AUTOSAR XML (schema 4-2-2)
package /STELLANTIS/EPT/ASWCs
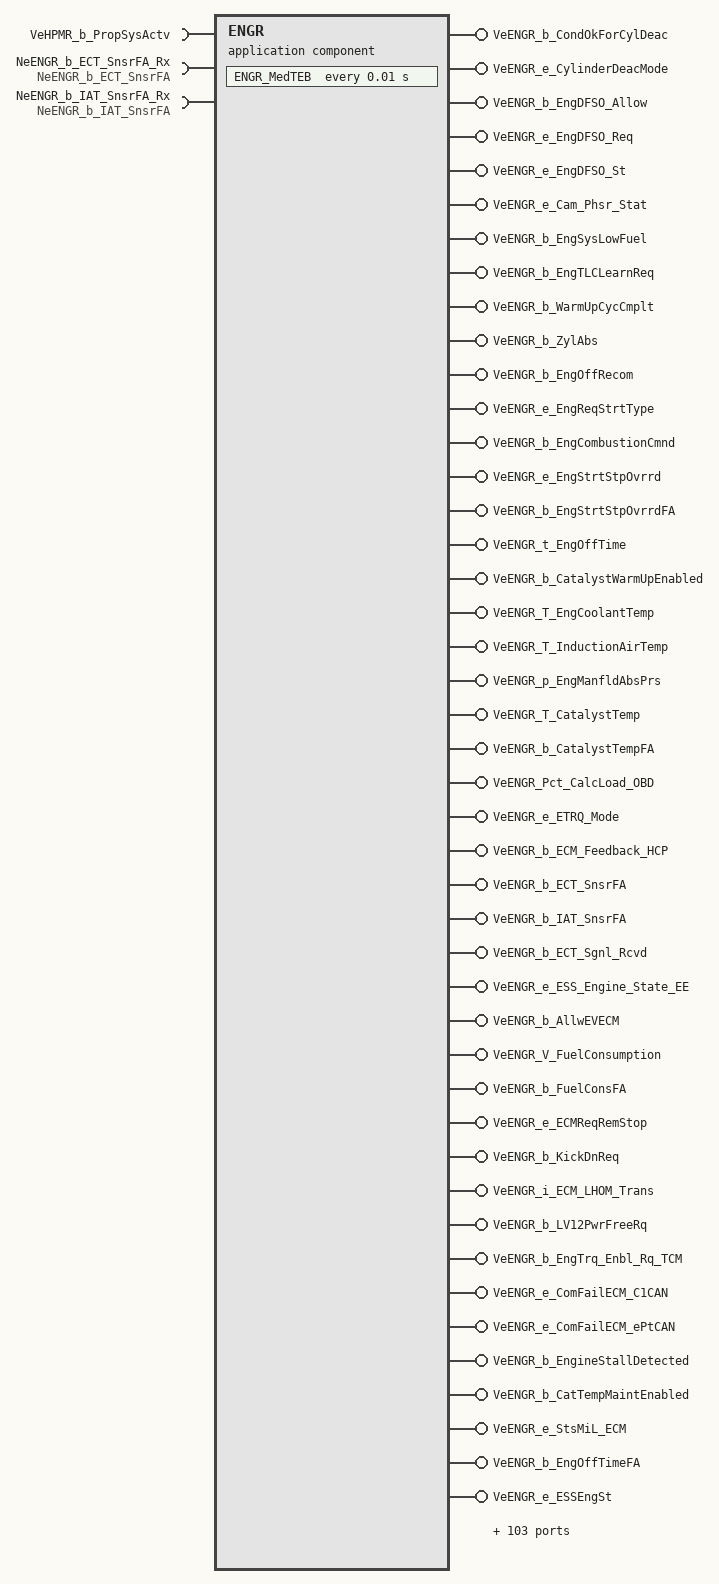
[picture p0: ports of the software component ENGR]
  application sw component type ENGR
    require port VeHPMR_b_PropSysActv: variation-point={short-label=vpVeHPMR_b_PropSysActv, sw-syscond=1}, nonqueued-receiver-com-spec{data-element=Value, init-value=0}, required-interface=VeHPMR_b_PropSysActv
    145 x provide port:
      VeENGR_b_CondOkForCylDeac: nonqueued-sender-com-spec{data-element=Value, init-value=0}, provided-interface=VeENGR_b_CondOkForCylDeac
      VeENGR_e_CylinderDeacMode: nonqueued-sender-com-spec{data-element=Value, init-value=CeENGR_e_AllCylindersActive}, provided-interface=VeENGR_e_CylinderDeacMode
      VeENGR_b_EngDFSO_Allow: nonqueued-sender-com-spec{data-element=Value, init-value=0}, provided-interface=VeENGR_b_EngDFSO_Allow
      VeENGR_e_EngDFSO_Req: nonqueued-sender-com-spec{data-element=Value, init-value=CeENGR_e_DFSO_Disabled}, provided-interface=VeENGR_e_EngDFSO_Req
      VeENGR_e_EngDFSO_St: nonqueued-sender-com-spec{data-element=Value, init-value=CeENGR_e_DFSO_Disabled}, provided-interface=VeENGR_e_EngDFSO_St
      VeENGR_e_Cam_Phsr_Stat: nonqueued-sender-com-spec{data-element=Value, init-value=CeENGR_e_AllPhasersParked}, provided-interface=VeENGR_e_Cam_Phsr_Stat
      VeENGR_b_EngSysLowFuel: nonqueued-sender-com-spec{data-element=Value, init-value=0}, provided-interface=VeENGR_b_EngSysLowFuel
      VeENGR_b_EngTLCLearnReq: nonqueued-sender-com-spec{data-element=Value, init-value=0}, provided-interface=VeENGR_b_EngTLCLearnReq
      VeENGR_b_WarmUpCycCmplt: nonqueued-sender-com-spec{data-element=Value, init-value=0}, provided-interface=VeENGR_b_WarmUpCycCmplt
      VeENGR_b_ZylAbs: nonqueued-sender-com-spec{data-element=Value, init-value=0}, provided-interface=VeENGR_b_ZylAbs
      VeENGR_b_EngOffRecom: nonqueued-sender-com-spec{data-element=Value, init-value=0}, provided-interface=VeENGR_b_EngOffRecom
      VeENGR_e_EngReqStrtType: variation-point={short-label=vpVeENGR_e_EngReqStrtType, sw-syscond=1}, nonqueued-sender-com-spec{data-element=Value, init-value=CeSTRR_e_NoAction}, provided-interface=VeENGR_e_EngReqStrtType
      VeENGR_b_EngCombustionCmnd: variation-point={short-label=vpVeENGR_b_EngCombustionCmnd, sw-syscond=1}, nonqueued-sender-com-spec{data-element=Value, init-value=0}, provided-interface=VeENGR_b_EngCombustionCmnd
      VeENGR_e_EngStrtStpOvrrd: variation-point={short-label=vpVeENGR_e_EngStrtStpOvrrd, sw-syscond=1}, nonqueued-sender-com-spec{data-element=Value, init-value=CeSTRR_e_NoOvrrd}, provided-interface=VeENGR_e_EngStrtStpOvrrd
      VeENGR_b_EngStrtStpOvrrdFA: nonqueued-sender-com-spec{data-element=Value, init-value=0}, provided-interface=VeENGR_b_EngStrtStpOvrrdFA
      VeENGR_t_EngOffTime: nonqueued-sender-com-spec{data-element=Value, init-value=0}, provided-interface=VeENGR_t_EngOffTime
      VeENGR_b_CatalystWarmUpEnabled: nonqueued-sender-com-spec{data-element=Value, init-value=0}, provided-interface=VeENGR_b_CatalystWarmUpEnabled
      VeENGR_T_EngCoolantTemp: nonqueued-sender-com-spec{data-element=Value, init-value=0}, provided-interface=VeENGR_T_EngCoolantTemp
      VeENGR_T_InductionAirTemp: nonqueued-sender-com-spec{data-element=Value, init-value=0}, provided-interface=VeENGR_T_InductionAirTemp
      VeENGR_p_EngManfldAbsPrs: nonqueued-sender-com-spec{data-element=Value, init-value=0}, provided-interface=VeENGR_p_EngManfldAbsPrs
      VeENGR_T_CatalystTemp: nonqueued-sender-com-spec{data-element=Value, init-value=0}, provided-interface=VeENGR_T_CatalystTemp
      VeENGR_b_CatalystTempFA: nonqueued-sender-com-spec{data-element=Value, init-value=0}, provided-interface=VeENGR_b_CatalystTempFA
      VeENGR_Pct_CalcLoad_OBD: nonqueued-sender-com-spec{data-element=Value, init-value=0}, provided-interface=VeENGR_Pct_CalcLoad_OBD
      VeENGR_e_ETRQ_Mode: variation-point={short-label=vpVeENGR_e_ETRQ_Mode, sw-syscond=1}, nonqueued-sender-com-spec{data-element=Value, init-value=CeENGR_e_Preposition}, provided-interface=VeENGR_e_ETRQ_Mode
      VeENGR_b_ECM_Feedback_HCP: nonqueued-sender-com-spec{data-element=Value, init-value=0}, provided-interface=VeENGR_b_ECM_Feedback_HCP
      VeENGR_b_ECT_SnsrFA: nonqueued-sender-com-spec{data-element=Value, init-value=0}, provided-interface=VeENGR_b_ECT_SnsrFA
      VeENGR_b_IAT_SnsrFA: nonqueued-sender-com-spec{data-element=Value, init-value=0}, provided-interface=VeENGR_b_IAT_SnsrFA
      VeENGR_b_ECT_Sgnl_Rcvd: nonqueued-sender-com-spec{data-element=Value, init-value=0}, provided-interface=VeENGR_b_ECT_Sgnl_Rcvd
      VeENGR_e_ESS_Engine_State_EE: variation-point={short-label=vpVeENGR_e_ESS_Engine_State_EE, sw-syscond=1}, nonqueued-sender-com-spec{data-element=Value, init-value=0}, provided-interface=VeENGR_e_ESS_Engine_State_EE
      VeENGR_b_AllwEVECM: nonqueued-sender-com-spec{data-element=Value, init-value=0}, provided-interface=VeENGR_b_AllwEVECM
      VeENGR_V_FuelConsumption: nonqueued-sender-com-spec{data-element=Value, init-value=0}, provided-interface=VeENGR_V_FuelConsumption
      VeENGR_b_FuelConsFA: nonqueued-sender-com-spec{data-element=Value, init-value=0}, provided-interface=VeENGR_b_FuelConsFA
      VeENGR_e_ECMReqRemStop: nonqueued-sender-com-spec{data-element=Value, init-value=CeENGR_e_Default}, provided-interface=VeENGR_e_ECMReqRemStop
      VeENGR_b_KickDnReq: nonqueued-sender-com-spec{data-element=Value, init-value=0}, provided-interface=VeENGR_b_KickDnReq
      VeENGR_i_ECM_LHOM_Trans: variation-point={short-label=vpVeENGR_i_ECM_LHOM_Trans, sw-syscond=1}, nonqueued-sender-com-spec{data-element=Value, init-value=0}, provided-interface=VeENGR_i_ECM_LHOM_Trans
      VeENGR_b_LV12PwrFreeRq: variation-point={short-label=vpVeENGR_b_LV12PwrFreeRq, sw-syscond=1}, nonqueued-sender-com-spec{data-element=Value, init-value=0}, provided-interface=VeENGR_b_LV12PwrFreeRq
      VeENGR_b_EngTrq_Enbl_Rq_TCM: variation-point={short-label=vpVeENGR_b_EngTrq_Enbl_Rq_TCM, sw-syscond=1}, nonqueued-sender-com-spec{data-element=Value, init-value=0}, provided-interface=VeENGR_b_EngTrq_Enbl_Rq_TCM
      VeENGR_e_ComFailECM_C1CAN: nonqueued-sender-com-spec{data-element=Value, init-value=CeENGR_e_NoFaultECM_C1}, provided-interface=VeENGR_e_ComFailECM_C1CAN
      VeENGR_e_ComFailECM_ePtCAN: nonqueued-sender-com-spec{data-element=Value, init-value=CeENGR_e_NoFaultECM_ePT}, provided-interface=VeENGR_e_ComFailECM_ePtCAN
      VeENGR_b_EngineStallDetected: nonqueued-sender-com-spec{data-element=Value, init-value=0}, provided-interface=VeENGR_b_EngineStallDetected
      VeENGR_b_CatTempMaintEnabled: nonqueued-sender-com-spec{data-element=Value, init-value=0}, provided-interface=VeENGR_b_CatTempMaintEnabled
      VeENGR_e_StsMiL_ECM: variation-point={short-label=vpVeENGR_e_StsMiL_ECM, sw-syscond=1}, nonqueued-sender-com-spec{data-element=Value, init-value=CeENGR_e_StsMiL_Fail_NotPrsnt}, provided-interface=VeENGR_e_StsMiL_ECM
      VeENGR_b_EngOffTimeFA: nonqueued-sender-com-spec{data-element=Value, init-value=0}, provided-interface=VeENGR_b_EngOffTimeFA
      VeENGR_e_ESSEngSt: nonqueued-sender-com-spec{data-element=Value, init-value=CeENGR_e_Stopped}, provided-interface=VeENGR_e_ESSEngSt
      VeENGR_Pct_PurgeIntensity: nonqueued-sender-com-spec{data-element=Value, init-value=0}, provided-interface=VeENGR_Pct_PurgeIntensity
      VeENGR_b_ECM_EVAllowed: nonqueued-sender-com-spec{data-element=Value, init-value=0}, provided-interface=VeENGR_b_ECM_EVAllowed
      VeENGR_e_EngineSts: nonqueued-sender-com-spec{data-element=Value, init-value=CeENGR_e_Engine_Off}, provided-interface=VeENGR_e_EngineSts
      VeENGR_b_FuelLevel2_SgnlRcvd: nonqueued-sender-com-spec{data-element=Value, init-value=0}, provided-interface=VeENGR_b_FuelLevel2_SgnlRcvd
      VeENGR_Pct_FuelLevel2: nonqueued-sender-com-spec{data-element=Value, init-value=0}, provided-interface=VeENGR_Pct_FuelLevel2
      VeENGR_m_CylAirIntake: nonqueued-sender-com-spec{data-element=Value, init-value=0}, provided-interface=VeENGR_m_CylAirIntake
      VeENGR_b_OilDil_EngMinPwrEnbl: nonqueued-sender-com-spec{data-element=Value, init-value=0}, provided-interface=VeENGR_b_OilDil_EngMinPwrEnbl
      VeENGR_P_OilDil_EngMinPwrReq: nonqueued-sender-com-spec{data-element=Value, init-value=0}, provided-interface=VeENGR_P_OilDil_EngMinPwrReq
      VeENGR_b_GasFlowActuator: nonqueued-sender-com-spec{data-element=Value, init-value=0}, provided-interface=VeENGR_b_GasFlowActuator
      VeENGR_e_EngineMaintenanceSts: nonqueued-sender-com-spec{data-element=Value, init-value=CeENGR_e_Inactive}, provided-interface=VeENGR_e_EngineMaintenanceSts
      FsftENGR_P_OilDil_EngMinPwrReq: server-com-spec=FsftENGR_P_OilDil_EngMinPwrReq, provided-interface=FsftENGR_P_OilDil_EngMinPwrReq
      FsftENGR_T_CatalystTemp: server-com-spec=FsftENGR_T_CatalystTemp, provided-interface=FsftENGR_T_CatalystTemp
      FsftENGR_T_EngCoolantTemp: server-com-spec=FsftENGR_T_EngCoolantTemp, provided-interface=FsftENGR_T_EngCoolantTemp
      FsftENGR_T_ExhaustGasTemp: server-com-spec=FsftENGR_T_ExhaustGasTemp, provided-interface=FsftENGR_T_ExhaustGasTemp
      FsftENGR_T_InductionAirTemp: server-com-spec=FsftENGR_T_InductionAirTemp, provided-interface=FsftENGR_T_InductionAirTemp
      FsftENGR_b_AllwEVECM: server-com-spec=FsftENGR_b_AllwEVECM, provided-interface=FsftENGR_b_AllwEVECM
      FsftENGR_b_CondOkForCylDeac: server-com-spec=FsftENGR_b_CondOkForCylDeac, provided-interface=FsftENGR_b_CondOkForCylDeac
      FsftENGR_b_ECMReqRemStop: server-com-spec=FsftENGR_b_ECMReqRemStop, provided-interface=FsftENGR_b_ECMReqRemStop
      FsftENGR_b_ECM_Feedback_HCP: server-com-spec=FsftENGR_b_ECM_Feedback_HCP, provided-interface=FsftENGR_b_ECM_Feedback_HCP
      FsftENGR_b_EXH_MASS_FLOW: server-com-spec=FsftENGR_b_EXH_MASS_FLOW, provided-interface=FsftENGR_b_EXH_MASS_FLOW
      FsftENGR_b_EngCombustionCmnd: server-com-spec=FsftENGR_b_EngCombustionCmnd, provided-interface=FsftENGR_b_EngCombustionCmnd
      FsftENGR_b_EngModeRun: server-com-spec=FsftENGR_b_EngModeRun, provided-interface=FsftENGR_b_EngModeRun
      FsftENGR_b_EngStrtStpOvrrd_C1: server-com-spec=FsftENGR_b_EngStrtStpOvrrd_C1, provided-interface=FsftENGR_b_EngStrtStpOvrrd_C1
      FsftENGR_b_Engine_Oil_Temp: server-com-spec=FsftENGR_b_Engine_Oil_Temp, provided-interface=FsftENGR_b_Engine_Oil_Temp
      FsftENGR_b_FuelConsumptionFA: server-com-spec=FsftENGR_b_FuelConsumptionFA, provided-interface=FsftENGR_b_FuelConsumptionFA
      FsftENGR_b_FuelLevel2: server-com-spec=FsftENGR_b_FuelLevel2, provided-interface=FsftENGR_b_FuelLevel2
      FsftENGR_b_KickDnReq: server-com-spec=FsftENGR_b_KickDnReq, provided-interface=FsftENGR_b_KickDnReq
      FsftENGR_b_OilDil_EngMinPwrEnbl: server-com-spec=FsftENGR_b_OilDil_EngMinPwrEnbl, provided-interface=FsftENGR_b_OilDil_EngMinPwrEnbl
      FsftENGR_b_PnLimitActvFlg: server-com-spec=FsftENGR_b_PnLimitActvFlg, provided-interface=FsftENGR_b_PnLimitActvFlg
      FsftENGR_b_StpNotAllwd: server-com-spec=FsftENGR_b_StpNotAllwd, provided-interface=FsftENGR_b_StpNotAllwd
      FsftENGR_b_StpNotAllwdID: server-com-spec=FsftENGR_b_StpNotAllwdID, provided-interface=FsftENGR_b_StpNotAllwdID
      FsftENGR_b_StrtNotAllwd: server-com-spec=FsftENGR_b_StrtNotAllwd, provided-interface=FsftENGR_b_StrtNotAllwd
      FsftENGR_b_StrtNotAllwdID: server-com-spec=FsftENGR_b_StrtNotAllwdID, provided-interface=FsftENGR_b_StrtNotAllwdID
      FsftENGR_e_ComFailDflt_C1CAN: server-com-spec=FsftENGR_e_ComFailDflt_C1CAN, provided-interface=FsftENGR_e_ComFailDflt_C1CAN
      FsftENGR_e_ComFailDflt_ePTCAN: server-com-spec=FsftENGR_e_ComFailDflt_ePTCAN, provided-interface=FsftENGR_e_ComFailDflt_ePTCAN
      FsftENGR_e_CylinderDeacMode: server-com-spec=FsftENGR_e_CylinderDeacMode, provided-interface=FsftENGR_e_CylinderDeacMode
      FsftENGR_e_EngStrtStpOvrrd: server-com-spec=FsftENGR_e_EngStrtStpOvrrd, provided-interface=FsftENGR_e_EngStrtStpOvrrd
      FsftENGR_p_EngManfldAbsPrs: server-com-spec=FsftENGR_p_EngManfldAbsPrs, provided-interface=FsftENGR_p_EngManfldAbsPrs
      PokeENGR_P_OilDil_EngMinPwrReq: server-com-spec{operation=PokeENGR_P_OilDil_EngMinPwrReq, queue-length=1}, provided-interface=PokeENGR_P_OilDil_EngMinPwrReq
      PokeENGR_Pct_CalcLoad_OBD: server-com-spec{operation=PokeENGR_Pct_CalcLoad_OBD, queue-length=1}, provided-interface=PokeENGR_Pct_CalcLoad_OBD
      PokeENGR_Pct_FuelLevel2: server-com-spec{operation=PokeENGR_Pct_FuelLevel2, queue-length=1}, provided-interface=PokeENGR_Pct_FuelLevel2
      PokeENGR_Pct_PurgeIntensity: server-com-spec{operation=PokeENGR_Pct_PurgeIntensity, queue-length=1}, provided-interface=PokeENGR_Pct_PurgeIntensity
      PokeENGR_T_CatalystTemp: server-com-spec{operation=PokeENGR_T_CatalystTemp, queue-length=1}, provided-interface=PokeENGR_T_CatalystTemp
      PokeENGR_T_EngCoolantTemp: server-com-spec{operation=PokeENGR_T_EngCoolantTemp, queue-length=1}, provided-interface=PokeENGR_T_EngCoolantTemp
      PokeENGR_T_Engine_Oil_Temp: server-com-spec{operation=PokeENGR_T_Engine_Oil_Temp, queue-length=1}, provided-interface=PokeENGR_T_Engine_Oil_Temp
      PokeENGR_T_ExhaustGasTemp: server-com-spec{operation=PokeENGR_T_ExhaustGasTemp, queue-length=1}, provided-interface=PokeENGR_T_ExhaustGasTemp
      PokeENGR_T_InductionAirTemp: server-com-spec{operation=PokeENGR_T_InductionAirTemp, queue-length=1}, provided-interface=PokeENGR_T_InductionAirTemp
      PokeENGR_V_FuelConsumption: server-com-spec{operation=PokeENGR_V_FuelConsumption, queue-length=1}, provided-interface=PokeENGR_V_FuelConsumption
      PokeENGR_b_AllwEVECM: server-com-spec{operation=PokeENGR_b_AllwEVECM, queue-length=1}, provided-interface=PokeENGR_b_AllwEVECM
      PokeENGR_b_CatTempMaintEnabled: server-com-spec{operation=PokeENGR_b_CatTempMaintEnabled, queue-length=1}, provided-interface=PokeENGR_b_CatTempMaintEnabled
      PokeENGR_b_CatalystWarmUpEnabled: server-com-spec{operation=PokeENGR_b_CatalystWarmUpEnabled, queue-length=1}, provided-interface=PokeENGR_b_CatalystWarmUpEnabled
      PokeENGR_b_CmprssnTest: server-com-spec{operation=PokeENGR_b_CmprssnTest, queue-length=1}, provided-interface=PokeENGR_b_CmprssnTest
      PokeENGR_b_CondOkForCylDeac: server-com-spec{operation=PokeENGR_b_CondOkForCylDeac, queue-length=1}, provided-interface=PokeENGR_b_CondOkForCylDeac
      PokeENGR_b_ECM_Feedback_HCP: server-com-spec{operation=PokeENGR_b_ECM_Feedback_HCP, queue-length=1}, provided-interface=PokeENGR_b_ECM_Feedback_HCP
      PokeENGR_b_ESS_ReqEngOff: server-com-spec{operation=PokeENGR_b_ESS_ReqEngOff, queue-length=1}, provided-interface=PokeENGR_b_ESS_ReqEngOff
      PokeENGR_b_ESS_ReqEngStart: server-com-spec{operation=PokeENGR_b_ESS_ReqEngStart, queue-length=1}, provided-interface=PokeENGR_b_ESS_ReqEngStart
      PokeENGR_b_EngCombustionCmnd: server-com-spec{operation=PokeENGR_b_EngCombustionCmnd, queue-length=1}, provided-interface=PokeENGR_b_EngCombustionCmnd
      PokeENGR_b_EngDFSO_Allow: server-com-spec{operation=PokeENGR_b_EngDFSO_Allow, queue-length=1}, provided-interface=PokeENGR_b_EngDFSO_Allow
      PokeENGR_b_EngMfLrnRPMCtrlReq: server-com-spec{operation=PokeENGR_b_EngMfLrnRPMCtrlReq, queue-length=1}, provided-interface=PokeENGR_b_EngMfLrnRPMCtrlReq
      PokeENGR_b_EngModeRun: server-com-spec{operation=PokeENGR_b_EngModeRun, queue-length=1}, provided-interface=PokeENGR_b_EngModeRun
      PokeENGR_b_EngOffRecom: server-com-spec{operation=PokeENGR_b_EngOffRecom, queue-length=1}, provided-interface=PokeENGR_b_EngOffRecom
      PokeENGR_b_EngSysDsbld: server-com-spec{operation=PokeENGR_b_EngSysDsbld, queue-length=1}, provided-interface=PokeENGR_b_EngSysDsbld
      PokeENGR_b_EngSysLowFuel: server-com-spec{operation=PokeENGR_b_EngSysLowFuel, queue-length=1}, provided-interface=PokeENGR_b_EngSysLowFuel
      PokeENGR_b_EngTLCLearnReq: server-com-spec{operation=PokeENGR_b_EngTLCLearnReq, queue-length=1}, provided-interface=PokeENGR_b_EngTLCLearnReq
      PokeENGR_b_EngTrq_Enbl_Rq_TCM: server-com-spec{operation=PokeENGR_b_EngTrq_Enbl_Rq_TCM, queue-length=1}, provided-interface=PokeENGR_b_EngTrq_Enbl_Rq_TCM
      PokeENGR_b_EngineStallDetected: server-com-spec{operation=PokeENGR_b_EngineStallDetected, queue-length=1}, provided-interface=PokeENGR_b_EngineStallDetected
      PokeENGR_b_GasFlowActuator: server-com-spec{operation=PokeENGR_b_GasFlowActuator, queue-length=1}, provided-interface=PokeENGR_b_GasFlowActuator
      PokeENGR_b_KickDnReq: server-com-spec{operation=PokeENGR_b_KickDnReq, queue-length=1}, provided-interface=PokeENGR_b_KickDnReq
      PokeENGR_b_LV12PwrFreeRq: server-com-spec{operation=PokeENGR_b_LV12PwrFreeRq, queue-length=1}, provided-interface=PokeENGR_b_LV12PwrFreeRq
      PokeENGR_b_OilDil_EngMinPwrEnbl: server-com-spec{operation=PokeENGR_b_OilDil_EngMinPwrEnbl, queue-length=1}, provided-interface=PokeENGR_b_OilDil_EngMinPwrEnbl
      PokeENGR_b_PCMSVSReq: server-com-spec{operation=PokeENGR_b_PCMSVSReq, queue-length=1}, provided-interface=PokeENGR_b_PCMSVSReq
      PokeENGR_b_PnLimitActvFlg: server-com-spec{operation=PokeENGR_b_PnLimitActvFlg, queue-length=1}, provided-interface=PokeENGR_b_PnLimitActvFlg
      PokeENGR_b_StpNotAllwd: server-com-spec{operation=PokeENGR_b_StpNotAllwd, queue-length=1}, provided-interface=PokeENGR_b_StpNotAllwd
      PokeENGR_b_StrtNotAllwd: server-com-spec{operation=PokeENGR_b_StrtNotAllwd, queue-length=1}, provided-interface=PokeENGR_b_StrtNotAllwd
      PokeENGR_b_WarmUpCycCmplt: server-com-spec{operation=PokeENGR_b_WarmUpCycCmplt, queue-length=1}, provided-interface=PokeENGR_b_WarmUpCycCmplt
      PokeENGR_b_ZylAbs: server-com-spec{operation=PokeENGR_b_ZylAbs, queue-length=1}, provided-interface=PokeENGR_b_ZylAbs
      PokeENGR_dm_EXH_MASS_FLOW: server-com-spec{operation=PokeENGR_dm_EXH_MASS_FLOW, queue-length=1}, provided-interface=PokeENGR_dm_EXH_MASS_FLOW
      PokeENGR_e_Cam_Phsr_Stat: server-com-spec{operation=PokeENGR_e_Cam_Phsr_Stat, queue-length=1}, provided-interface=PokeENGR_e_Cam_Phsr_Stat
      PokeENGR_e_ComFail_C1CAN: server-com-spec{operation=PokeENGR_e_ComFail_C1CAN, queue-length=1}, provided-interface=PokeENGR_e_ComFail_C1CAN
      PokeENGR_e_ComFail_ePTCAN: server-com-spec{operation=PokeENGR_e_ComFail_ePTCAN, queue-length=1}, provided-interface=PokeENGR_e_ComFail_ePTCAN
      PokeENGR_e_CylinderDeacMode: server-com-spec{operation=PokeENGR_e_CylinderDeacMode, queue-length=1}, provided-interface=PokeENGR_e_CylinderDeacMode
      PokeENGR_e_ECMReqRemStop: server-com-spec{operation=PokeENGR_e_ECMReqRemStop, queue-length=1}, provided-interface=PokeENGR_e_ECMReqRemStop
      PokeENGR_e_ESSEngSt: server-com-spec{operation=PokeENGR_e_ESSEngSt, queue-length=1}, provided-interface=PokeENGR_e_ESSEngSt
      PokeENGR_e_ETRQ_Mode: server-com-spec{operation=PokeENGR_e_ETRQ_Mode, queue-length=1}, provided-interface=PokeENGR_e_ETRQ_Mode
      PokeENGR_e_EngDFSO_Req: server-com-spec{operation=PokeENGR_e_EngDFSO_Req, queue-length=1}, provided-interface=PokeENGR_e_EngDFSO_Req
      PokeENGR_e_EngDFSO_St: server-com-spec{operation=PokeENGR_e_EngDFSO_St, queue-length=1}, provided-interface=PokeENGR_e_EngDFSO_St
      PokeENGR_e_EngReqStrtType: server-com-spec{operation=PokeENGR_e_EngReqStrtType, queue-length=1}, provided-interface=PokeENGR_e_EngReqStrtType
      PokeENGR_e_EngStrtStpOvrrd: server-com-spec{operation=PokeENGR_e_EngStrtStpOvrrd, queue-length=1}, provided-interface=PokeENGR_e_EngStrtStpOvrrd
      PokeENGR_e_EngStrtStpOvrrd_C1: server-com-spec{operation=PokeENGR_e_EngStrtStpOvrrd_C1, queue-length=1}, provided-interface=PokeENGR_e_EngStrtStpOvrrd_C1
      PokeENGR_e_EngineMaintenanceSts: server-com-spec{operation=PokeENGR_e_EngineMaintenanceSts, queue-length=1}, provided-interface=PokeENGR_e_EngineMaintenanceSts
      PokeENGR_e_HybActEngTorqRespType: server-com-spec{operation=PokeENGR_e_HybActEngTorqRespType, queue-length=1}, provided-interface=PokeENGR_e_HybActEngTorqRespType
      PokeENGR_e_StpNotAllwdID: server-com-spec{operation=PokeENGR_e_StpNotAllwdID, queue-length=1}, provided-interface=PokeENGR_e_StpNotAllwdID
      PokeENGR_e_StrtNotAllwdID: server-com-spec{operation=PokeENGR_e_StrtNotAllwdID, queue-length=1}, provided-interface=PokeENGR_e_StrtNotAllwdID
      PokeENGR_e_StsMil_ECM: server-com-spec{operation=PokeENGR_e_StsMil_ECM, queue-length=1}, provided-interface=PokeENGR_e_StsMil_ECM
      PokeENGR_i_ECM_LHOM_Trans: server-com-spec{operation=PokeENGR_i_ECM_LHOM_Trans, queue-length=1}, provided-interface=PokeENGR_i_ECM_LHOM_Trans
      PokeENGR_m_CylAirIntake: server-com-spec{operation=PokeENGR_m_CylAirIntake, queue-length=1}, provided-interface=PokeENGR_m_CylAirIntake
      PokeENGR_p_EngManfldAbsPrs: server-com-spec{operation=PokeENGR_p_EngManfldAbsPrs, queue-length=1}, provided-interface=PokeENGR_p_EngManfldAbsPrs
      PokeENGR_t_EngOffTime: server-com-spec{operation=PokeENGR_t_EngOffTime, queue-length=1}, provided-interface=PokeENGR_t_EngOffTime
      TmotENGR_b_EngCoolantTemp: server-com-spec=TmotENGR_b_EngCoolantTemp, provided-interface=TmotENGR_b_EngCoolantTemp
      TmotENGR_b_EngStrtStpOvrrd_C1: server-com-spec=TmotENGR_b_EngStrtStpOvrrd_C1, provided-interface=TmotENGR_b_EngStrtStpOvrrd_C1
      TmotENGR_b_FuelLevel2: server-com-spec=TmotENGR_b_FuelLevel2, provided-interface=TmotENGR_b_FuelLevel2
    require port NeENGR_b_ECT_SnsrFA_Rx: nv-require-com-spec{init-value=0, variable=NeENGR_b_ECT_SnsrFA}, required-interface=NeENGR_b_ECT_SnsrFA
    require port NeENGR_b_IAT_SnsrFA_Rx: nv-require-com-spec{init-value=0, variable=NeENGR_b_IAT_SnsrFA}, required-interface=NeENGR_b_IAT_SnsrFA
    provide port NeENGR_b_ECT_SnsrFA: nv-provide-com-spec{ram-block-init-value=0, variable=NeENGR_b_ECT_SnsrFA}, provided-interface=NeENGR_b_ECT_SnsrFA
    provide port NeENGR_b_IAT_SnsrFA: nv-provide-com-spec{ram-block-init-value=0, variable=NeENGR_b_IAT_SnsrFA}, provided-interface=NeENGR_b_IAT_SnsrFA
    behavior IB_ENGR: data-type-mapping=msADTtoIDTMapping, handle-termination-and-restart=NO-SUPPORT
      timing event Event_MedTEB: start-on-event=ENGR_MedTEB, period=0.01
      init event Event_ENGR_ac_Init: start-on-event=ENGR_ac_Init
      init event Event_PwrOn: start-on-event=ENGR_PwrOn
      init event Event_PwrOff: start-on-event=ENGR_PwrOff
      explicit-inter-runnable-variables:
        6 x data, all with category=VALUE, sw-calibration-access=READ-ONLY:
          VeENGR_e_CylinderDeacMode_write_IRV: type=TeENGR_e_CylinderDeacModes, init-value=CeENGR_e_AllCylindersActive
          VeENGR_b_EngStrtStpOvrrdFA_write_IRV: type=Boolean, init-value=0
          VeENGR_e_EngStrtStpOvrrd_C1_write_IRV: type=TeENGR_e_ESS_Engine_State, init-value=CeENGR_e_ENS_STOPPED
          VeENGR_b_EngStrtStpOvrrdFA_C1_write_IRV: type=Boolean, init-value=0
          VeENGR_b_EngStrtStpOvrrd_SgnlRcvd_C1_write_IRV: type=Boolean, init-value=0
          VeENGR_e_EngReqStrtType_IRV: type=TeSTRR_e_EngStrtStopType, init-value=CeSTRR_e_NoAction
      4 x runnable:
        ENGR_ac_Init
          data-send-points:
            14 x access:
              OUT_VeENGR_e_CylinderDeacMode_Value: accessed-variable=VeENGR_e_CylinderDeacMode.Value
              OUT_VeENGR_e_EngDFSO_Req_Value: accessed-variable=VeENGR_e_EngDFSO_Req.Value
              OUT_VeENGR_e_EngDFSO_St_Value: accessed-variable=VeENGR_e_EngDFSO_St.Value
              OUT_VeENGR_e_Cam_Phsr_Stat_Value: accessed-variable=VeENGR_e_Cam_Phsr_Stat.Value
              OUT_VeENGR_e_EngReqStrtType_Value: accessed-variable=VeENGR_e_EngReqStrtType.Value, variation-point={short-label=vpOUT_VeENGR_e_EngReqStrtType_Value, sw-syscond=1}
              OUT_VeENGR_e_EngStrtStpOvrrd_Value: accessed-variable=VeENGR_e_EngStrtStpOvrrd.Value, variation-point={short-label=vpOUT_VeENGR_e_EngStrtStpOvrrd_Value, sw-syscond=1}
              OUT_VeENGR_e_ETRQ_Mode_Value: accessed-variable=VeENGR_e_ETRQ_Mode.Value, variation-point={short-label=vpOUT_VeENGR_e_ETRQ_Mode_Value, sw-syscond=1}
              OUT_VeENGR_e_ECMReqRemStop_Value: accessed-variable=VeENGR_e_ECMReqRemStop.Value
              OUT_VeENGR_e_ComFailECM_C1CAN_Value: accessed-variable=VeENGR_e_ComFailECM_C1CAN.Value
              OUT_VeENGR_e_ComFailECM_ePtCAN_Value: accessed-variable=VeENGR_e_ComFailECM_ePtCAN.Value
              OUT_VeENGR_e_StsMiL_ECM_Value: accessed-variable=VeENGR_e_StsMiL_ECM.Value, variation-point={short-label=vpOUT_VeENGR_e_StsMiL_ECM_Value, sw-syscond=1}
              OUT_VeENGR_e_ESSEngSt_Value: accessed-variable=VeENGR_e_ESSEngSt.Value
              OUT_VeENGR_e_EngineSts_Value: accessed-variable=VeENGR_e_EngineSts.Value
              OUT_VeENGR_e_EngineMaintenanceSts_Value: accessed-variable=VeENGR_e_EngineMaintenanceSts.Value
        ENGR_PwrOn
          data-receive-point-by-arguments:
            access IN_NeENGR_b_ECT_SnsrFA_Rx_NeENGR_b_ECT_SnsrFA: accessed-variable=NeENGR_b_ECT_SnsrFA_Rx.NeENGR_b_ECT_SnsrFA
            access IN_NeENGR_b_IAT_SnsrFA_Rx_NeENGR_b_IAT_SnsrFA: accessed-variable=NeENGR_b_IAT_SnsrFA_Rx.NeENGR_b_IAT_SnsrFA
          data-send-points:
            54 x access:
              OUT_VeENGR_p_EngManfldAbsPrs_Value: accessed-variable=VeENGR_p_EngManfldAbsPrs.Value
              OUT_VeENGR_T_InductionAirTemp_Value: accessed-variable=VeENGR_T_InductionAirTemp.Value
              OUT_VeENGR_b_CatalystTempFA_Value: accessed-variable=VeENGR_b_CatalystTempFA.Value
              OUT_VeENGR_T_CatalystTemp_Value: accessed-variable=VeENGR_T_CatalystTemp.Value
              OUT_VeENGR_T_EngCoolantTemp_Value: accessed-variable=VeENGR_T_EngCoolantTemp.Value
              OUT_VeENGR_Pct_CalcLoad_OBD_Value: accessed-variable=VeENGR_Pct_CalcLoad_OBD.Value
              OUT_VeENGR_b_ECT_Sgnl_Rcvd_Value: accessed-variable=VeENGR_b_ECT_Sgnl_Rcvd.Value
              OUT_VeENGR_b_EngTLCLearnReq_Value: accessed-variable=VeENGR_b_EngTLCLearnReq.Value
              OUT_VeENGR_b_WarmUpCycCmplt_Value: accessed-variable=VeENGR_b_WarmUpCycCmplt.Value
              OUT_VeENGR_b_ZylAbs_Value: accessed-variable=VeENGR_b_ZylAbs.Value
              OUT_VeENGR_b_EngOffRecom_Value: accessed-variable=VeENGR_b_EngOffRecom.Value
              OUT_VeENGR_t_EngOffTime_Value: accessed-variable=VeENGR_t_EngOffTime.Value
              OUT_VeENGR_b_EngDFSO_Allow_Value: accessed-variable=VeENGR_b_EngDFSO_Allow.Value
              OUT_VeENGR_Pct_PurgeIntensity_Value: accessed-variable=VeENGR_Pct_PurgeIntensity.Value
              OUT_VeENGR_b_CatalystWarmUpEnabled_Value: accessed-variable=VeENGR_b_CatalystWarmUpEnabled.Value
              OUT_VeENGR_b_ECM_Feedback_HCP_Value: accessed-variable=VeENGR_b_ECM_Feedback_HCP.Value
              OUT_VeENGR_b_EngStrtStpOvrrdFA_Value: accessed-variable=VeENGR_b_EngStrtStpOvrrdFA.Value
              OUT_VeENGR_b_CondOkForCylDeac_Value: accessed-variable=VeENGR_b_CondOkForCylDeac.Value
              OUT_VeENGR_b_EngOffTimeFA_Value: accessed-variable=VeENGR_b_EngOffTimeFA.Value
              OUT_VeENGR_b_AllwEVECM_Value: accessed-variable=VeENGR_b_AllwEVECM.Value
              OUT_VeENGR_e_ECMReqRemStop_Value: accessed-variable=VeENGR_e_ECMReqRemStop.Value
              OUT_VeENGR_b_KickDnReq_Value: accessed-variable=VeENGR_b_KickDnReq.Value
              OUT_VeENGR_e_CylinderDeacMode_Value: accessed-variable=VeENGR_e_CylinderDeacMode.Value
              OUT_VeENGR_b_EngineStallDetected_Value: accessed-variable=VeENGR_b_EngineStallDetected.Value
              OUT_VeENGR_b_CatTempMaintEnabled_Value: accessed-variable=VeENGR_b_CatTempMaintEnabled.Value
              OUT_VeENGR_V_FuelConsumption_Value: accessed-variable=VeENGR_V_FuelConsumption.Value
              OUT_VeENGR_e_ComFailECM_ePtCAN_Value: accessed-variable=VeENGR_e_ComFailECM_ePtCAN.Value
              OUT_VeENGR_e_ComFailECM_C1CAN_Value: accessed-variable=VeENGR_e_ComFailECM_C1CAN.Value
              OUT_VeENGR_e_ESSEngSt_Value: accessed-variable=VeENGR_e_ESSEngSt.Value
              OUT_VeENGR_e_EngDFSO_Req_Value: accessed-variable=VeENGR_e_EngDFSO_Req.Value
              OUT_VeENGR_b_FuelConsFA_Value: accessed-variable=VeENGR_b_FuelConsFA.Value
              OUT_VeENGR_e_EngDFSO_St_Value: accessed-variable=VeENGR_e_EngDFSO_St.Value
              OUT_VeENGR_e_Cam_Phsr_Stat_Value: accessed-variable=VeENGR_e_Cam_Phsr_Stat.Value
              OUT_VeENGR_b_EngSysLowFuel_Value: accessed-variable=VeENGR_b_EngSysLowFuel.Value
              OUT_VeENGR_b_IAT_SnsrFA_Value: accessed-variable=VeENGR_b_IAT_SnsrFA.Value
              OUT_VeENGR_e_StsMiL_ECM_Value: accessed-variable=VeENGR_e_StsMiL_ECM.Value, variation-point={short-label=vpOUT_VeENGR_e_StsMiL_ECM_Value, sw-syscond=1}
              OUT_VeENGR_b_EngCombustionCmnd_Value: accessed-variable=VeENGR_b_EngCombustionCmnd.Value, variation-point={short-label=vpOUT_VeENGR_b_EngCombustionCmnd_Value, sw-syscond=1}
              OUT_VeENGR_e_EngStrtStpOvrrd_Value: accessed-variable=VeENGR_e_EngStrtStpOvrrd.Value, variation-point={short-label=vpOUT_VeENGR_e_EngStrtStpOvrrd_Value, sw-syscond=1}
              OUT_VeENGR_e_ESS_Engine_State_EE_Value: accessed-variable=VeENGR_e_ESS_Engine_State_EE.Value, variation-point={short-label=vpOUT_VeENGR_e_ESS_Engine_State_EE_Value, sw-syscond=1}
              OUT_VeENGR_e_ETRQ_Mode_Value: accessed-variable=VeENGR_e_ETRQ_Mode.Value, variation-point={short-label=vpOUT_VeENGR_e_ETRQ_Mode_Value, sw-syscond=1}
              OUT_VeENGR_i_ECM_LHOM_Trans_Value: accessed-variable=VeENGR_i_ECM_LHOM_Trans.Value, variation-point={short-label=vpOUT_VeENGR_i_ECM_LHOM_Trans_Value, sw-syscond=1}
              OUT_VeENGR_b_LV12PwrFreeRq_Value: accessed-variable=VeENGR_b_LV12PwrFreeRq.Value, variation-point={short-label=vpOUT_VeENGR_b_LV12PwrFreeRq_Value, sw-syscond=1}
              OUT_VeENGR_b_EngTrq_Enbl_Rq_TCM_Value: accessed-variable=VeENGR_b_EngTrq_Enbl_Rq_TCM.Value, variation-point={short-label=vpOUT_VeENGR_b_EngTrq_Enbl_Rq_TCM_Value, sw-syscond=1}
              OUT_VeENGR_b_ECT_SnsrFA_Value: accessed-variable=VeENGR_b_ECT_SnsrFA.Value
              OUT_VeENGR_b_ECM_EVAllowed_Value: accessed-variable=VeENGR_b_ECM_EVAllowed.Value
              OUT_VeENGR_e_EngineSts_Value: accessed-variable=VeENGR_e_EngineSts.Value
              OUT_VeENGR_e_EngReqStrtType_Value: accessed-variable=VeENGR_e_EngReqStrtType.Value, variation-point={short-label=vpOUT_VeENGR_e_EngReqStrtType_Value, sw-syscond=1}
              OUT_VeENGR_b_FuelLevel2_SgnlRcvd_Value: accessed-variable=VeENGR_b_FuelLevel2_SgnlRcvd.Value
              OUT_VeENGR_Pct_FuelLevel2_Value: accessed-variable=VeENGR_Pct_FuelLevel2.Value
              OUT_VeENGR_m_CylAirIntake_Value: accessed-variable=VeENGR_m_CylAirIntake.Value
              OUT_VeENGR_b_OilDil_EngMinPwrEnbl_Value: accessed-variable=VeENGR_b_OilDil_EngMinPwrEnbl.Value
              OUT_VeENGR_P_OilDil_EngMinPwrReq_Value: accessed-variable=VeENGR_P_OilDil_EngMinPwrReq.Value
              OUT_VeENGR_b_GasFlowActuator_Value: accessed-variable=VeENGR_b_GasFlowActuator.Value
              OUT_VeENGR_e_EngineMaintenanceSts_Value: accessed-variable=VeENGR_e_EngineMaintenanceSts.Value
          written-local-variables:
            6 x access:
              WV_VeENGR_b_EngStrtStpOvrrdFA_C1_write_IRV: accessed-variable=VeENGR_b_EngStrtStpOvrrdFA_C1_write_IRV
              WV_VeENGR_b_EngStrtStpOvrrdFA_write_IRV: accessed-variable=VeENGR_b_EngStrtStpOvrrdFA_write_IRV
              WV_VeENGR_b_EngStrtStpOvrrd_SgnlRcvd_C1_write_IRV: accessed-variable=VeENGR_b_EngStrtStpOvrrd_SgnlRcvd_C1_write_IRV
              WV_VeENGR_e_CylinderDeacMode_write_IRV: accessed-variable=VeENGR_e_CylinderDeacMode_write_IRV
              WV_VeENGR_e_EngReqStrtType_IRV: accessed-variable=VeENGR_e_EngReqStrtType_IRV
              WV_VeENGR_e_EngStrtStpOvrrd_C1_write_IRV: accessed-variable=VeENGR_e_EngStrtStpOvrrd_C1_write_IRV
        ENGR_MedTEB
          data-receive-point-by-arguments:
            access IN_VeHPMR_b_PropSysActv_Value: accessed-variable=VeHPMR_b_PropSysActv.Value, variation-point={short-label=vpIN_VeHPMR_b_PropSysActv_Value, sw-syscond=1}
          data-send-points:
            13 x access:
              OUT_VeENGR_b_EngCombustionCmnd_Value: accessed-variable=VeENGR_b_EngCombustionCmnd.Value, variation-point={short-label=vpOUT_VeENGR_b_EngCombustionCmnd_Value, sw-syscond=1}
              OUT_VeENGR_e_EngStrtStpOvrrd_Value: accessed-variable=VeENGR_e_EngStrtStpOvrrd.Value, variation-point={short-label=vpOUT_VeENGR_e_EngStrtStpOvrrd_Value, sw-syscond=1}
              OUT_VeENGR_e_ESS_Engine_State_EE_Value: accessed-variable=VeENGR_e_ESS_Engine_State_EE.Value, variation-point={short-label=vpOUT_VeENGR_e_ESS_Engine_State_EE_Value, sw-syscond=1}
              OUT_VeENGR_i_ECM_LHOM_Trans_Value: accessed-variable=VeENGR_i_ECM_LHOM_Trans.Value, variation-point={short-label=vpOUT_VeENGR_i_ECM_LHOM_Trans_Value, sw-syscond=1}
              OUT_VeENGR_b_LV12PwrFreeRq_Value: accessed-variable=VeENGR_b_LV12PwrFreeRq.Value, variation-point={short-label=vpOUT_VeENGR_b_LV12PwrFreeRq_Value, sw-syscond=1}
              OUT_VeENGR_b_EngTrq_Enbl_Rq_TCM_Value: accessed-variable=VeENGR_b_EngTrq_Enbl_Rq_TCM.Value, variation-point={short-label=vpOUT_VeENGR_b_EngTrq_Enbl_Rq_TCM_Value, sw-syscond=1}
              OUT_VeENGR_b_ECM_EVAllowed_Value: accessed-variable=VeENGR_b_ECM_EVAllowed.Value
              OUT_VeENGR_e_EngineSts_Value: accessed-variable=VeENGR_e_EngineSts.Value
              OUT_VeENGR_b_IAT_SnsrFA_Value: accessed-variable=VeENGR_b_IAT_SnsrFA.Value
              OUT_VeENGR_e_StsMiL_ECM_Value: accessed-variable=VeENGR_e_StsMiL_ECM.Value, variation-point={short-label=vpOUT_VeENGR_e_StsMiL_ECM_Value, sw-syscond=1}
              OUT_VeENGR_e_ETRQ_Mode_Value: accessed-variable=VeENGR_e_ETRQ_Mode.Value, variation-point={short-label=vpOUT_VeENGR_e_ETRQ_Mode_Value, sw-syscond=1}
              OUT_VeENGR_b_ECT_SnsrFA_Value: accessed-variable=VeENGR_b_ECT_SnsrFA.Value
              OUT_VeENGR_e_EngReqStrtType_Value: accessed-variable=VeENGR_e_EngReqStrtType.Value, variation-point={short-label=vpOUT_VeENGR_e_EngReqStrtType_Value, sw-syscond=1}
        ENGR_PwrOff
          data-send-points:
            access OUT_NeENGR_b_ECT_SnsrFA_NeENGR_b_ECT_SnsrFA: accessed-variable=NeENGR_b_ECT_SnsrFA.NeENGR_b_ECT_SnsrFA
            access OUT_NeENGR_b_IAT_SnsrFA_NeENGR_b_IAT_SnsrFA: accessed-variable=NeENGR_b_IAT_SnsrFA.NeENGR_b_IAT_SnsrFA
      4 x variation point proxy, all with category=CONDITION:
        Variant_ENGR_1: condition-access=0
        Variant_ENGR_2: condition-access=0
        Variant_ENGR_3: condition-access=1
        Variant_ENGR_4: condition-access=0
